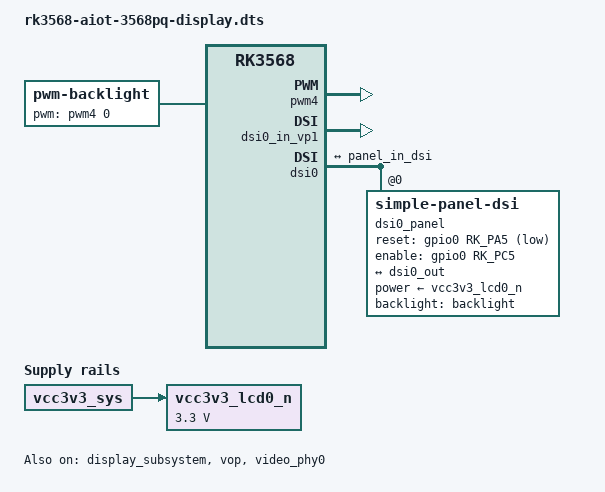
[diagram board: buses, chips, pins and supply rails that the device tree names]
// SPDX-License-Identifier: (GPL-2.0+ OR MIT)
/* Offline display candidate: original 720x720 panel on tested UART/RNG base.
 * Board validation is separate. Keep loader allocations but never map its logo.
 */
#include "rk3568-aiot-3568pq-uart.dts"
#include <dt-bindings/display/drm_mipi_dsi.h>

/ {
    vcc3v3_lcd0_n: vcc3v3-lcd0-n {
        compatible = "regulator-fixed";
        regulator-name = "vcc3v3_lcd0_n";
        regulator-min-microvolt = <3300000>;
        regulator-max-microvolt = <3300000>;
        regulator-boot-on;
        vin-supply = <&vcc3v3_sys>;
        /* Preserved Android flag; the original regulator has no GPIO. */
        enable-active-high;
        status = "okay";
        regulator-state-mem {
            regulator-off-in-suspend;
        };
    };

    backlight: backlight {
        compatible = "pwm-backlight";
        pwms = <&pwm4 0 25000 0>;
        /* Original table; remain dark until a connected panel is verified. */
        brightness-levels = <
            0 20 20 21 21 22 22 23 23 24 24 25 25 26 26 27
            27 28 28 29 29 30 30 31 31 32 32 33 33 34 34 35
            35 36 36 37 37 38 38 39 40 41 42 43 44 45 46 47
            48 49 50 51 52 53 54 55 56 57 58 59 60 61 62 63
            64 65 66 67 68 69 70 71 72 73 74 75 76 77 78 79
            80 81 82 83 84 85 86 87 88 89 90 91 92 93 94 95
            96 97 98 99 100 101 102 103 104 105 106 107 108 109 110 111
            112 113 114 115 116 117 118 119 120 121 122 123 124 125 126 127
            128 129 130 131 132 133 134 135 136 137 138 139 140 141 142 143
            144 145 146 147 148 149 150 151 152 153 154 155 156 157 158 159
            160 161 162 163 164 165 166 167 168 169 170 171 172 173 174 175
            176 177 178 179 180 181 182 183 184 185 186 187 188 189 190 191
            192 193 194 195 196 197 198 199 200 201 202 203 204 205 206 207
            208 209 210 211 212 213 214 215 216 217 218 219 220 221 222 223
            224 225 226 227 228 229 230 231 232 233 234 235 236 237 238 239
            240 241 242 243 244 245 246 247 248 249 250 251 252 253 254 255
        >;
        default-brightness-level = <0>;
    };
};

&display_subsystem {
    /delete-property/ memory-region;
    /delete-property/ memory-region-names;
    status = "okay";
};

/* No bootloader logo takeover: preserve the reserved bytes without mapping. */
&route_dsi0 { status = "disabled"; };
&route_dsi1 { status = "disabled"; };
&route_edp { status = "disabled"; };
&route_hdmi { status = "disabled"; };
&route_lvds { status = "disabled"; };
&route_rgb { status = "disabled"; };

&vop { status = "okay"; };
&vop_mmu { status = "okay"; };
&video_phy0 { status = "okay"; };
&pwm4 { status = "okay"; };
&dsi0_in_vp0 { status = "disabled"; };
&dsi0_in_vp1 { status = "okay"; };

&dsi0 {
    status = "okay";
    ports {
        port@1 {
            reg = <1>;
            dsi0_out: endpoint {
                remote-endpoint = <&panel_in_dsi>;
            };
        };
    };
    dsi0_panel: panel@0 {
        compatible = "simple-panel-dsi";
        reg = <0>;
        status = "okay";
        power-supply = <&vcc3v3_lcd0_n>;
        backlight = <&backlight>;
        reset-gpios = <&gpio0 RK_PA5 GPIO_ACTIVE_LOW>;
        enable-gpios = <&gpio0 RK_PC5 GPIO_ACTIVE_HIGH>;
        prepare-delay-ms = <50>;
        reset-delay-ms = <120>;
        init-delay-ms = <120>;
        enable-delay-ms = <220>;
        disable-delay-ms = <120>;
        unprepare-delay-ms = <120>;
        screen-type = <2>;
        dsi,lanes = <4>;
        dsi,format = <MIPI_DSI_FMT_RGB888>;
        /* 5.10 flag bit9 is EOT; bit10 non-continuous clock remains unset. */
        dsi,flags = <(MIPI_DSI_MODE_VIDEO | MIPI_DSI_MODE_VIDEO_BURST |
                      MIPI_DSI_MODE_EOT_PACKET | MIPI_DSI_MODE_LPM)>;
        panel-init-sequence = [
            13 02 02 ff 30
            13 02 02 ff 52
            13 02 02 ff 01
            13 02 02 e3 04
            13 02 02 08 0e
            13 02 02 25 0f
            13 02 02 28 5f
            13 02 02 29 c2
            13 02 02 2a cf
            13 02 02 37 5c
            13 02 02 38 67
            13 02 02 39 5d
            13 02 02 44 00
            13 02 02 49 3c
            13 02 02 59 fe
            13 02 02 5c 00
            13 02 02 80 20
            13 02 02 91 77
            13 02 02 92 77
            13 02 02 98 ca
            13 02 02 99 51
            13 02 02 9a c1
            13 02 02 9b 59
            13 02 02 a0 55
            13 02 02 a1 50
            13 02 02 a4 9c
            13 02 02 a7 02
            13 02 02 a8 01
            13 02 02 a9 21
            13 02 02 aa fc
            13 02 02 ab 28
            13 02 02 ac 06
            13 02 02 ad 06
            13 02 02 ae 06
            13 02 02 af 03
            13 02 02 b0 08
            13 02 02 b1 26
            13 02 02 b2 28
            13 02 02 b3 28
            13 02 02 b4 33
            13 02 02 b5 08
            13 02 02 b6 26
            13 02 02 b7 08
            13 02 02 b8 26
            13 02 02 f0 00
            13 02 02 f6 c0
            13 02 02 c0 00
            13 02 02 c1 00
            13 02 02 c3 0f
            13 02 02 2c 22
            13 02 02 ff 30
            13 02 02 ff 52
            13 02 02 ff 02
            13 02 02 b1 0c
            13 02 02 d1 02
            13 02 02 b4 3f
            13 02 02 d4 3f
            13 02 02 b2 02
            13 02 02 d2 00
            13 02 02 b3 3c
            13 02 02 d3 32
            13 02 02 b6 02
            13 02 02 d6 00
            13 02 02 b7 31
            13 02 02 d7 27
            13 02 02 c1 0a
            13 02 02 e1 00
            13 02 02 b8 0f
            13 02 02 d8 05
            13 02 02 b9 00
            13 02 02 d9 00
            13 02 02 bd 13
            13 02 02 dd 0d
            13 02 02 bc 11
            13 02 02 dc 09
            13 02 02 bb 10
            13 02 02 db 06
            13 02 02 ba 12
            13 02 02 da 08
            13 02 02 be 16
            13 02 02 de 16
            13 02 02 bf 0c
            13 02 02 df 0c
            13 02 02 c0 13
            13 02 02 e0 13
            13 02 02 b5 3f
            13 02 02 d5 2e
            13 02 02 b0 02
            13 02 02 d0 03
            13 02 02 ff 30
            13 02 02 ff 52
            13 02 02 ff 03
            13 02 02 08 85
            13 02 02 09 86
            13 02 02 0a 83
            13 02 02 0b 84
            13 02 02 20 00
            13 02 02 21 00
            13 02 02 22 00
            13 02 02 23 00
            13 02 02 27 03
            13 02 02 28 22
            13 02 02 29 22
            13 02 02 2a d7
            13 02 02 2b d7
            13 02 02 34 11
            13 02 02 35 01
            13 02 02 36 01
            13 02 02 37 03
            13 02 02 40 81
            13 02 02 41 82
            13 02 02 42 01
            13 02 02 43 80
            13 02 02 44 22
            13 02 02 45 d5
            13 02 02 46 d4
            13 02 02 47 22
            13 02 02 48 d7
            13 02 02 49 d6
            13 02 02 50 85
            13 02 02 51 86
            13 02 02 52 83
            13 02 02 53 84
            13 02 02 54 22
            13 02 02 55 d1
            13 02 02 56 d0
            13 02 02 57 22
            13 02 02 58 d3
            13 02 02 59 d2
            13 02 02 7e 03
            13 02 02 7f 02
            13 02 02 80 0f
            13 02 02 81 0f
            13 02 02 82 0e
            13 02 02 83 0e
            13 02 02 84 02
            13 02 02 85 04
            13 02 02 86 04
            13 02 02 87 05
            13 02 02 88 05
            13 02 02 89 06
            13 02 02 8a 06
            13 02 02 8b 07
            13 02 02 8c 07
            13 02 02 8d 0f
            13 02 02 8e 0f
            13 02 02 8f 0d
            13 02 02 90 0d
            13 02 02 91 0c
            13 02 02 92 0c
            13 02 02 93 00
            13 02 02 94 01
            13 02 02 96 0f
            13 02 02 97 0f
            13 02 02 98 0e
            13 02 02 99 0e
            13 02 02 9a 02
            13 02 02 9b 04
            13 02 02 9c 04
            13 02 02 9d 05
            13 02 02 9e 05
            13 02 02 9f 06
            13 02 02 a0 06
            13 02 02 a1 07
            13 02 02 a2 07
            13 02 02 a3 0f
            13 02 02 a4 0f
            13 02 02 a5 0d
            13 02 02 a6 0d
            13 02 02 a7 0c
            13 02 02 a8 0c
            13 02 02 a9 00
            13 02 02 aa 01
            13 02 02 ff 30
            13 02 02 ff 52
            13 02 02 ff 00
            13 02 02 36 02
            13 02 02 53 2c
            05 78 01 11
            05 78 01 29
        ];
        panel-exit-sequence = [05 00 01 28 05 00 01 10];
        port {
            panel_in_dsi: endpoint {
                remote-endpoint = <&dsi0_out>;
            };
        };
        display-timings {
            native-mode = <&dsi0_timing>;
            dsi0_timing: timing0 {
                clock-frequency = <35500000>;
                hactive = <720>;
                hfront-porch = <24>;
                hsync-len = <2>;
                hback-porch = <30>;
                vactive = <720>;
                vfront-porch = <16>;
                vsync-len = <2>;
                vback-porch = <8>;
                hsync-active = <0>;
                vsync-active = <0>;
                de-active = <0>;
                pixelclk-active = <0>;
            };
        };
    };
};
